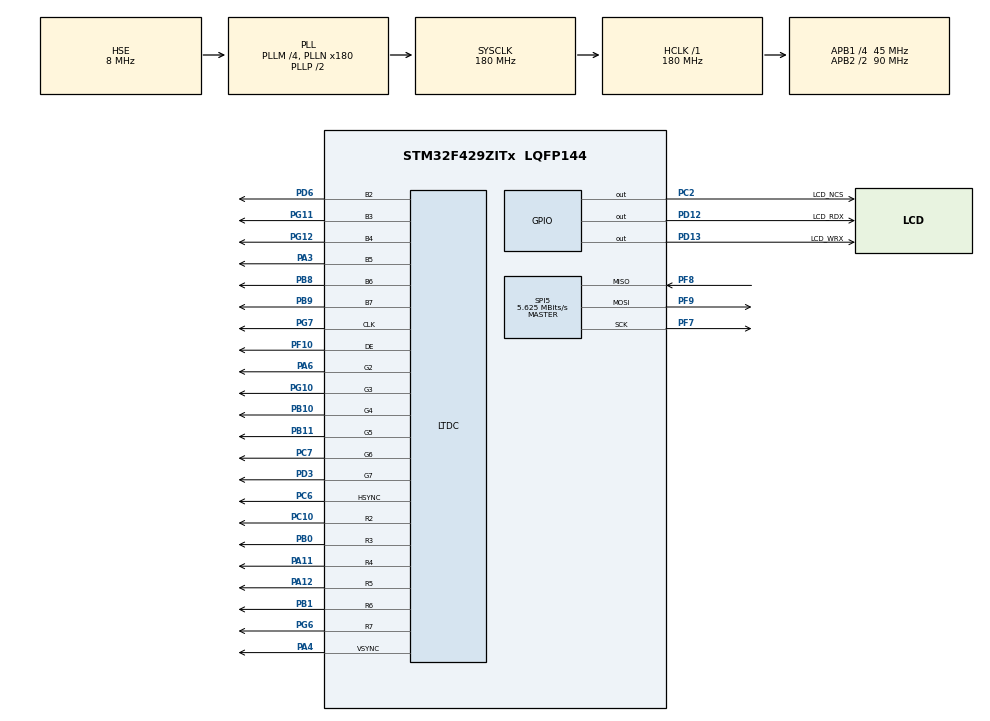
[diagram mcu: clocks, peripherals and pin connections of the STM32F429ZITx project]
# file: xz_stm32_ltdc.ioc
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LTDC.ActiveH=240
LTDC.ActiveW=320
LTDC.Blue_L0=255
LTDC.Green_L0=255
LTDC.HBP=20
LTDC.HFP=10
LTDC.HSync=10
LTDC.Layers=0
LTDC.PixelFormat_L0=LTDC_PIXEL_FORMAT_L8
LTDC.Red_L0=255
LTDC.VFP=4
LTDC.VSync=2
LTDC.WindowX0_L0=31
LTDC.WindowX1_L0=288
LTDC.WindowY0_L0=23
LTDC.WindowY1_L0=215
Mcu.Family=STM32F4
Mcu.Name=STM32F429ZITx
Mcu.Package=LQFP144
NVIC.PriorityGroup=NVIC_PRIORITYGROUP_4
PA11.GPIO_Speed=GPIO_SPEED_FREQ_VERY_HIGH
PA11.Mode=RGB666
PA11.Signal=LTDC_R4
PA12.GPIO_Speed=GPIO_SPEED_FREQ_VERY_HIGH
PA12.Mode=RGB666
PA12.Signal=LTDC_R5
PA3.GPIO_Speed=GPIO_SPEED_FREQ_VERY_HIGH
PA3.Mode=RGB666
PA3.Signal=LTDC_B5
PA4.GPIO_Speed=GPIO_SPEED_FREQ_VERY_HIGH
PA4.Mode=RGB666
PA4.Signal=LTDC_VSYNC
PA6.GPIO_Speed=GPIO_SPEED_FREQ_VERY_HIGH
PA6.Mode=RGB666
PA6.Signal=LTDC_G2
PB0.GPIO_Speed=GPIO_SPEED_FREQ_VERY_HIGH
PB0.Mode=RGB666
PB0.Signal=LTDC_R3
PB1.GPIO_Speed=GPIO_SPEED_FREQ_VERY_HIGH
PB1.Mode=RGB666
PB1.Signal=LTDC_R6
PB10.GPIO_Speed=GPIO_SPEED_FREQ_VERY_HIGH
PB10.Mode=RGB666
PB10.Signal=LTDC_G4
PB11.GPIO_Speed=GPIO_SPEED_FREQ_VERY_HIGH
PB11.Mode=RGB666
PB11.Signal=LTDC_G5
PB8.GPIO_Speed=GPIO_SPEED_FREQ_VERY_HIGH
PB8.Mode=RGB666
PB8.Signal=LTDC_B6
PB9.GPIO_Speed=GPIO_SPEED_FREQ_VERY_HIGH
PB9.Mode=RGB666
PB9.Signal=LTDC_B7
PC10.GPIO_Speed=GPIO_SPEED_FREQ_VERY_HIGH
PC10.Mode=RGB666
PC10.Signal=LTDC_R2
PC2.GPIO_Label=LCD_NCS
PC2.GPIO_Speed=GPIO_SPEED_FREQ_VERY_HIGH
PC2.Signal=GPIO_Output
PC6.GPIO_Speed=GPIO_SPEED_FREQ_VERY_HIGH
PC6.Mode=RGB666
PC6.Signal=LTDC_HSYNC
PC7.GPIO_Speed=GPIO_SPEED_FREQ_VERY_HIGH
PC7.Mode=RGB666
PC7.Signal=LTDC_G6
PD12.GPIO_Label=LCD_RDX
PD12.GPIO_Speed=GPIO_SPEED_FREQ_VERY_HIGH
PD12.Signal=GPIO_Output
PD13.GPIO_Label=LCD_WRX
PD13.GPIO_Speed=GPIO_SPEED_FREQ_VERY_HIGH
PD13.Signal=GPIO_Output
PD3.GPIO_Speed=GPIO_SPEED_FREQ_VERY_HIGH
PD3.Mode=RGB666
PD3.Signal=LTDC_G7
PD6.GPIO_Speed=GPIO_SPEED_FREQ_VERY_HIGH
PD6.Mode=RGB666
PD6.Signal=LTDC_B2
PF10.GPIO_Speed=GPIO_SPEED_FREQ_VERY_HIGH
PF10.Mode=RGB666
PF10.Signal=LTDC_DE
PF7.Mode=Full_Duplex_Master
PF7.Signal=SPI5_SCK
PF8.Mode=Full_Duplex_Master
PF8.Signal=SPI5_MISO
PF9.Mode=Full_Duplex_Master
PF9.Signal=SPI5_MOSI
PG10.GPIO_Speed=GPIO_SPEED_FREQ_VERY_HIGH
PG10.Mode=RGB666
PG10.Signal=LTDC_G3
PG11.GPIO_Speed=GPIO_SPEED_FREQ_VERY_HIGH
PG11.Mode=RGB666
PG11.Signal=LTDC_B3
PG12.GPIO_Speed=GPIO_SPEED_FREQ_VERY_HIGH
PG12.Mode=RGB666
PG12.Signal=LTDC_B4
PG6.GPIO_Speed=GPIO_SPEED_FREQ_VERY_HIGH
PG6.Mode=RGB666
PG6.Signal=LTDC_R7
PG7.GPIO_Speed=GPIO_SPEED_FREQ_VERY_HIGH
PG7.Mode=RGB666
PG7.Signal=LTDC_CLK
PH0/OSC_IN.Mode=HSE-External-Oscillator
PH0/OSC_IN.Signal=RCC_OSC_IN
PH1/OSC_OUT.Mode=HSE-External-Oscillator
PH1/OSC_OUT.Signal=RCC_OSC_OUT
ProjectManager.HeapSize=0x200
ProjectManager.StackSize=0x400
ProjectManager.TargetToolchain=SW4STM32
RCC.48MHZClocksFreq_Value=90000000
RCC.AHBFreq_Value=180000000
RCC.APB1CLKDivider=RCC_HCLK_DIV4
RCC.APB1Freq_Value=45000000
RCC.APB1TimFreq_Value=90000000
RCC.APB2CLKDivider=RCC_HCLK_DIV2
RCC.APB2Freq_Value=90000000
RCC.APB2TimFreq_Value=180000000
RCC.CortexFreq_Value=180000000
RCC.HCLKFreq_Value=180000000
RCC.HSE_VALUE=8000000
RCC.HSI_VALUE=16000000
RCC.LSE_VALUE=32768
RCC.PLLM=4
RCC.PLLN=180
RCC.PLLSAIDivR=RCC_PLLSAIDIVR_8
RCC.PLLSAIN=56
RCC.PLLSourceVirtual=RCC_PLLSOURCE_HSE
RCC.SYSCLKFreq_VALUE=180000000
RCC.SYSCLKSource=RCC_SYSCLKSOURCE_PLLCLK
RCC.VCOOutputFreq_Value=360000000
SPI5.BaudRatePrescaler=SPI_BAUDRATEPRESCALER_16
SPI5.CalculateBaudRate=5.625 MBits/s
SPI5.Direction=SPI_DIRECTION_2LINES
SPI5.Mode=SPI_MODE_MASTER
SPI5.VirtualType=VM_MASTER
board=xz_stm32_ltdc

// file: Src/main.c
/**
  ******************************************************************************
  * File Name          : main.c
  * Description        : Main program body
  ******************************************************************************
  ** This notice applies to any and all portions of this file
  * that are not between comment pairs USER CODE BEGIN and
  * USER CODE END. Other portions of this file, whether
  * inserted by the user or by software development tools
  * are owned by their respective copyright owners.
  *
  * COPYRIGHT(c) 2018 STMicroelectronics
  *
  * Redistribution and use in source and binary forms, with or without modification,
  * are permitted provided that the following conditions are met:
  *   1. Redistributions of source code must retain the above copyright notice,
  *      this list of conditions and the following disclaimer.
  *   2. Redistributions in binary form must reproduce the above copyright notice,
  *      this list of conditions and the following disclaimer in the documentation
  *      and/or other materials provided with the distribution.
  *   3. Neither the name of STMicroelectronics nor the names of its contributors
  *      may be used to endorse or promote products derived from this software
  *      without specific prior written permission.
  *
  * THIS SOFTWARE IS PROVIDED BY THE COPYRIGHT HOLDERS AND CONTRIBUTORS "AS IS"
  * AND ANY EXPRESS OR IMPLIED WARRANTIES, INCLUDING, BUT NOT LIMITED TO, THE
  * IMPLIED WARRANTIES OF MERCHANTABILITY AND FITNESS FOR A PARTICULAR PURPOSE ARE
  * DISCLAIMED. IN NO EVENT SHALL THE COPYRIGHT HOLDER OR CONTRIBUTORS BE LIABLE
  * FOR ANY DIRECT, INDIRECT, INCIDENTAL, SPECIAL, EXEMPLARY, OR CONSEQUENTIAL
  * DAMAGES (INCLUDING, BUT NOT LIMITED TO, PROCUREMENT OF SUBSTITUTE GOODS OR
  * SERVICES; LOSS OF USE, DATA, OR PROFITS; OR BUSINESS INTERRUPTION) HOWEVER
  * CAUSED AND ON ANY THEORY OF LIABILITY, WHETHER IN CONTRACT, STRICT LIABILITY,
  * OR TORT (INCLUDING NEGLIGENCE OR OTHERWISE) ARISING IN ANY WAY OUT OF THE USE
  * OF THIS SOFTWARE, EVEN IF ADVISED OF THE POSSIBILITY OF SUCH DAMAGE.
  *
  ******************************************************************************
  */

#include "main.h"
#include "stm32f4xx_hal.h"
#include "ltdc.h"
#include "spi.h"
#include "gpio.h"

/* USER CODE BEGIN Includes */
#include "lcd_ili9341_ltdc.h"

/* USER CODE END Includes */

/* USER CODE BEGIN PV */
/* Private variables ---------------------------------------------------------*/

/* USER CODE END PV */

void SystemClock_Config(void);

/* USER CODE BEGIN PFP */
/* Private function prototypes -----------------------------------------------*/

/* USER CODE END PFP */

int main(void)
{

  /* MCU Configuration----------------------------------------------------------*/

  /* Reset of all peripherals, Initializes the Flash interface and the Systick. */
  HAL_Init();

  /* Configure the system clock */
  SystemClock_Config();

  /* Initialize all configured peripherals */
  MX_GPIO_Init();
  MX_SPI5_Init();
  MX_LTDC_Init();

  /* USER CODE BEGIN 2 */
  ili9341_Init();
  /* USER CODE END 2 */

  /* Infinite loop */
  while (1)
  {

  }

}

/** System Clock Configuration
*/
void SystemClock_Config(void)
{

  RCC_OscInitTypeDef RCC_OscInitStruct;
  RCC_ClkInitTypeDef RCC_ClkInitStruct;
  RCC_PeriphCLKInitTypeDef PeriphClkInitStruct;

    /**Configure the main internal regulator output voltage
    */
  __HAL_RCC_PWR_CLK_ENABLE();

  __HAL_PWR_VOLTAGESCALING_CONFIG(PWR_REGULATOR_VOLTAGE_SCALE1);

    /**Initializes the CPU, AHB and APB busses clocks
    */
  RCC_OscInitStruct.OscillatorType = RCC_OSCILLATORTYPE_HSE;
  RCC_OscInitStruct.HSEState = RCC_HSE_ON;
  RCC_OscInitStruct.PLL.PLLState = RCC_PLL_ON;
  RCC_OscInitStruct.PLL.PLLSource = RCC_PLLSOURCE_HSE;
  RCC_OscInitStruct.PLL.PLLM = 4;
  RCC_OscInitStruct.PLL.PLLN = 180;
  RCC_OscInitStruct.PLL.PLLP = RCC_PLLP_DIV2;
  RCC_OscInitStruct.PLL.PLLQ = 4;
  if (HAL_RCC_OscConfig(&RCC_OscInitStruct) != HAL_OK)
  {
    _Error_Handler(__FILE__, __LINE__);
  }

    /**Activate the Over-Drive mode
    */
  if (HAL_PWREx_EnableOverDrive() != HAL_OK)
  {
    _Error_Handler(__FILE__, __LINE__);
  }

    /**Initializes the CPU, AHB and APB busses clocks
    */
  RCC_ClkInitStruct.ClockType = RCC_CLOCKTYPE_HCLK|RCC_CLOCKTYPE_SYSCLK
                              |RCC_CLOCKTYPE_PCLK1|RCC_CLOCKTYPE_PCLK2;
  RCC_ClkInitStruct.SYSCLKSource = RCC_SYSCLKSOURCE_PLLCLK;
  RCC_ClkInitStruct.AHBCLKDivider = RCC_SYSCLK_DIV1;
  RCC_ClkInitStruct.APB1CLKDivider = RCC_HCLK_DIV4;
  RCC_ClkInitStruct.APB2CLKDivider = RCC_HCLK_DIV2;

  if (HAL_RCC_ClockConfig(&RCC_ClkInitStruct, FLASH_LATENCY_5) != HAL_OK)
  {
    _Error_Handler(__FILE__, __LINE__);
  }

  PeriphClkInitStruct.PeriphClockSelection = RCC_PERIPHCLK_LTDC;
  PeriphClkInitStruct.PLLSAI.PLLSAIN = 56;
  PeriphClkInitStruct.PLLSAI.PLLSAIR = 2;
  PeriphClkInitStruct.PLLSAIDivR = RCC_PLLSAIDIVR_8;
  if (HAL_RCCEx_PeriphCLKConfig(&PeriphClkInitStruct) != HAL_OK)
  {
    _Error_Handler(__FILE__, __LINE__);
  }

    /**Configure the Systick interrupt time
    */
  HAL_SYSTICK_Config(HAL_RCC_GetHCLKFreq()/1000);

    /**Configure the Systick
    */
  HAL_SYSTICK_CLKSourceConfig(SYSTICK_CLKSOURCE_HCLK);

  /* SysTick_IRQn interrupt configuration */
  HAL_NVIC_SetPriority(SysTick_IRQn, 0, 0);
}

void _Error_Handler(char * file, int line)
{
  while(1)
  {
  }
}

/************************ (C) COPYRIGHT STMicroelectronics *****END OF FILE****/
